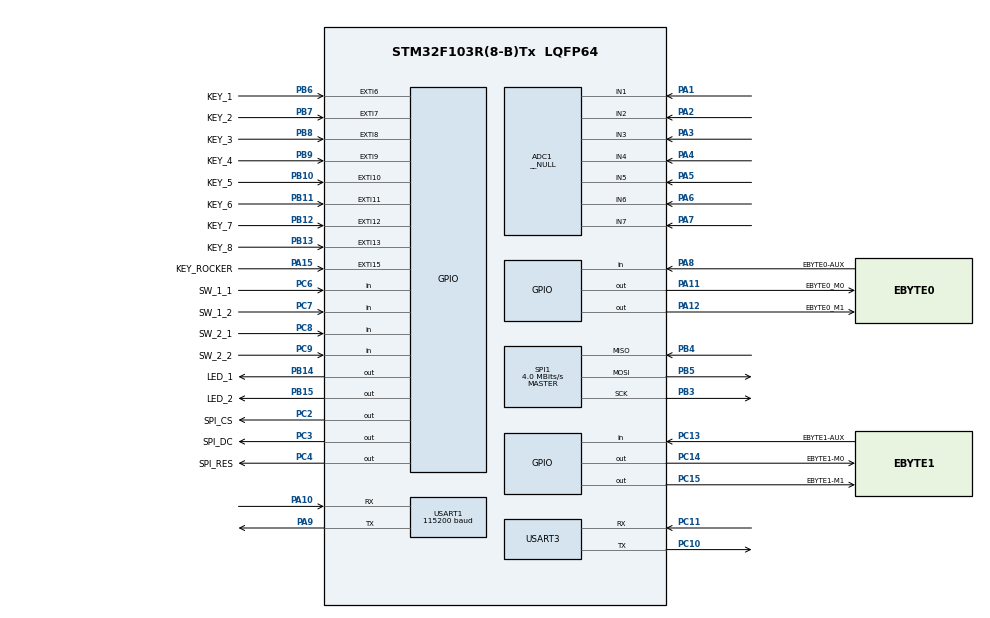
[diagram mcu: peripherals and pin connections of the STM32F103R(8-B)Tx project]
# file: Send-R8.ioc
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ADC1.Channel-0\#ChannelRegularConversion=ADC_CHANNEL_1
ADC1.Channel-1\#ChannelRegularConversion=ADC_CHANNEL_2
ADC1.Channel-2\#ChannelRegularConversion=ADC_CHANNEL_3
ADC1.Channel-3\#ChannelRegularConversion=ADC_CHANNEL_4
ADC1.Channel-4\#ChannelRegularConversion=ADC_CHANNEL_5
ADC1.Channel-5\#ChannelRegularConversion=ADC_CHANNEL_6
ADC1.Channel-6\#ChannelRegularConversion=ADC_CHANNEL_7
ADC1.Channel-IN1=ADC_CHANNEL_1
ADC1.Channel-IN4=ADC_CHANNEL_4
ADC1.Channel-IN5=ADC_CHANNEL_5
ADC1.Channel-IN6=ADC_CHANNEL_6
ADC1.Channel-IN7=ADC_CHANNEL_7
ADC1.ContinuousConvMode=DISABLE
ADC1.DataAlign=ADC_DATAALIGN_RIGHT
ADC1.DiscontinuousConvMode=DISABLE
ADC1.EnableAnalogWatchDog=false
ADC1.EnableInjectedConversion=DISABLE
ADC1.EnableRegularConversion=ENABLE
ADC1.ExternalTrigConv=ADC_EXTERNALTRIGCONV_T3_TRGO
ADC1.Mode=__NULL
ADC1.NbrOfConversion=7
ADC1.Rank-0\#ChannelRegularConversion=1
ADC1.Rank-1\#ChannelRegularConversion=2
ADC1.Rank-2\#ChannelRegularConversion=3
ADC1.Rank-3\#ChannelRegularConversion=4
ADC1.Rank-4\#ChannelRegularConversion=5
ADC1.Rank-5\#ChannelRegularConversion=6
ADC1.Rank-6\#ChannelRegularConversion=7
ADC1.SamplingTime-0\#ChannelRegularConversion=ADC_SAMPLETIME_7CYCLES_5
ADC1.SamplingTime-1\#ChannelRegularConversion=ADC_SAMPLETIME_7CYCLES_5
ADC1.SamplingTime-2\#ChannelRegularConversion=ADC_SAMPLETIME_7CYCLES_5
ADC1.SamplingTime-3\#ChannelRegularConversion=ADC_SAMPLETIME_7CYCLES_5
ADC1.SamplingTime-4\#ChannelRegularConversion=ADC_SAMPLETIME_7CYCLES_5
ADC1.SamplingTime-5\#ChannelRegularConversion=ADC_SAMPLETIME_7CYCLES_5
ADC1.SamplingTime-6\#ChannelRegularConversion=ADC_SAMPLETIME_7CYCLES_5
ADC1.ScanConvMode=ADC_SCAN_ENABLE
ADC1.master=1
Dma.ADC1.1.Direction=DMA_PERIPH_TO_MEMORY
Dma.ADC1.1.Instance=DMA1_Channel1
Dma.ADC1.1.MemDataAlignment=DMA_MDATAALIGN_WORD
Dma.ADC1.1.MemInc=DMA_MINC_ENABLE
Dma.ADC1.1.Mode=DMA_CIRCULAR
Dma.ADC1.1.PeriphDataAlignment=DMA_PDATAALIGN_WORD
Dma.ADC1.1.PeriphInc=DMA_PINC_DISABLE
Dma.ADC1.1.Priority=DMA_PRIORITY_HIGH
Dma.Request0=USART1_TX
Dma.Request1=ADC1
Dma.USART1_TX.0.Direction=DMA_MEMORY_TO_PERIPH
Dma.USART1_TX.0.Instance=DMA1_Channel4
Dma.USART1_TX.0.MemDataAlignment=DMA_MDATAALIGN_BYTE
Dma.USART1_TX.0.MemInc=DMA_MINC_ENABLE
Dma.USART1_TX.0.Mode=DMA_CIRCULAR
Dma.USART1_TX.0.PeriphDataAlignment=DMA_PDATAALIGN_BYTE
Dma.USART1_TX.0.PeriphInc=DMA_PINC_DISABLE
Dma.USART1_TX.0.Priority=DMA_PRIORITY_MEDIUM
Mcu.Family=STM32F1
Mcu.Name=STM32F103R(8-B)Tx
Mcu.Package=LQFP64
NVIC.DMA1_Channel1_IRQn=true\:0\:0\:false\:false\:true\:false\:true\:true
NVIC.DMA1_Channel4_IRQn=true\:0\:0\:false\:false\:true\:false\:true\:true
NVIC.EXTI15_10_IRQn=true\:1\:0\:true\:false\:true\:true\:true\:true
NVIC.EXTI9_5_IRQn=true\:1\:0\:true\:false\:true\:true\:true\:true
NVIC.PriorityGroup=NVIC_PRIORITYGROUP_4
NVIC.TIM2_IRQn=true\:0\:0\:false\:false\:true\:true\:true\:true
NVIC.USART1_IRQn=true\:5\:0\:false\:false\:true\:true\:true\:true
PA1.Signal=ADCx_IN1
PA10.Mode=Asynchronous
PA10.Signal=USART1_RX
PA11.GPIO_Label=EBYTE0_M0
PA11.GPIO_PuPd=GPIO_PULLDOWN
PA11.PinState=GPIO_PIN_RESET
PA11.Signal=GPIO_Output
PA12.GPIO_Label=EBYTE0_M1
PA12.GPIO_PuPd=GPIO_PULLDOWN
PA12.Signal=GPIO_Output
PA13.Mode=Serial_Wire
PA13.Signal=SYS_JTMS-SWDIO
PA14.Mode=Serial_Wire
PA14.Signal=SYS_JTCK-SWCLK
PA15.GPIO_Label=KEY_ROCKER
PA15.GPIO_ModeDefaultEXTI=GPIO_MODE_IT_RISING_FALLING
PA15.GPIO_PuPd=GPIO_PULLUP
PA15.Signal=GPXTI15
PA2.Signal=ADCx_IN2
PA3.Signal=ADCx_IN3
PA4.Signal=ADCx_IN4
PA5.Signal=ADCx_IN5
PA6.Signal=ADCx_IN6
PA7.Signal=ADCx_IN7
PA8.GPIO_Label=EBYTE0-AUX
PA8.Signal=GPIO_Input
PA9.Mode=Asynchronous
PA9.Signal=USART1_TX
PB10.GPIO_Label=KEY_5
PB10.GPIO_ModeDefaultEXTI=GPIO_MODE_IT_RISING_FALLING
PB10.GPIO_PuPd=GPIO_PULLUP
PB10.Signal=GPXTI10
PB11.GPIO_Label=KEY_6
PB11.GPIO_ModeDefaultEXTI=GPIO_MODE_IT_RISING_FALLING
PB11.GPIO_PuPd=GPIO_PULLUP
PB11.Signal=GPXTI11
PB12.GPIO_Label=KEY_7
PB12.GPIO_ModeDefaultEXTI=GPIO_MODE_IT_RISING_FALLING
PB12.GPIO_PuPd=GPIO_PULLUP
PB12.Signal=GPXTI12
PB13.GPIO_Label=KEY_8
PB13.GPIO_ModeDefaultEXTI=GPIO_MODE_IT_RISING_FALLING
PB13.GPIO_PuPd=GPIO_PULLUP
PB13.Signal=GPXTI13
PB14.GPIO_Label=LED_1
PB14.GPIO_PuPd=GPIO_PULLDOWN
PB14.PinState=GPIO_PIN_RESET
PB14.Signal=GPIO_Output
PB15.GPIO_Label=LED_2
PB15.GPIO_PuPd=GPIO_PULLUP
PB15.PinState=GPIO_PIN_SET
PB15.Signal=GPIO_Output
PB3.Mode=Full_Duplex_Master
PB3.Signal=SPI1_SCK
PB4.Mode=Full_Duplex_Master
PB4.Signal=SPI1_MISO
PB5.Mode=Full_Duplex_Master
PB5.Signal=SPI1_MOSI
PB6.GPIO_Label=KEY_1
PB6.GPIO_ModeDefaultEXTI=GPIO_MODE_IT_RISING_FALLING
PB6.GPIO_PuPd=GPIO_PULLUP
PB6.Signal=GPXTI6
PB7.GPIO_Label=KEY_2
PB7.GPIO_ModeDefaultEXTI=GPIO_MODE_IT_RISING_FALLING
PB7.GPIO_PuPd=GPIO_PULLUP
PB7.Signal=GPXTI7
PB8.GPIO_Label=KEY_3
PB8.GPIO_ModeDefaultEXTI=GPIO_MODE_IT_RISING_FALLING
PB8.GPIO_PuPd=GPIO_PULLUP
PB8.Signal=GPXTI8
PB9.GPIO_Label=KEY_4
PB9.GPIO_ModeDefaultEXTI=GPIO_MODE_IT_RISING_FALLING
PB9.GPIO_PuPd=GPIO_PULLUP
PB9.Signal=GPXTI9
PC10.Mode=Asynchronous
PC10.Signal=USART3_TX
PC11.Mode=Asynchronous
PC11.Signal=USART3_RX
PC13-TAMPER-RTC.GPIO_Label=EBYTE1-AUX
PC13-TAMPER-RTC.GPIO_PuPd=GPIO_PULLDOWN
PC13-TAMPER-RTC.Signal=GPIO_Input
PC14-OSC32_IN.GPIO_Label=EBYTE1-M0
PC14-OSC32_IN.GPIO_PuPd=GPIO_PULLDOWN
PC14-OSC32_IN.Signal=GPIO_Output
PC15-OSC32_OUT.GPIO_Label=EBYTE1-M1
PC15-OSC32_OUT.GPIO_PuPd=GPIO_PULLDOWN
PC15-OSC32_OUT.Signal=GPIO_Output
PC2.GPIO_Label=SPI_CS
PC2.Signal=GPIO_Output
PC3.GPIO_Label=SPI_DC
PC3.Signal=GPIO_Output
PC4.GPIO_Label=SPI_RES
PC4.Signal=GPIO_Output
PC6.GPIO_Label=SW_1_1
PC6.GPIO_PuPd=GPIO_PULLUP
PC6.Signal=GPIO_Input
PC7.GPIO_Label=SW_1_2
PC7.GPIO_PuPd=GPIO_PULLUP
PC7.Signal=GPIO_Input
PC8.GPIO_Label=SW_2_1
PC8.GPIO_PuPd=GPIO_PULLUP
PC8.Signal=GPIO_Input
PC9.GPIO_Label=SW_2_2
PC9.GPIO_PuPd=GPIO_PULLUP
PC9.Signal=GPIO_Input
PD0-OSC_IN.Mode=HSE-External-Oscillator
PD0-OSC_IN.Signal=RCC_OSC_IN
PD1-OSC_OUT.Mode=HSE-External-Oscillator
PD1-OSC_OUT.Signal=RCC_OSC_OUT
ProjectManager.HeapSize=0x200
ProjectManager.StackSize=0x400
ProjectManager.TargetToolchain=MDK-ARM V5.27
RCC.APB1Freq_Value=8000000
RCC.APB2Freq_Value=8000000
SH.ADCx_IN1.0=ADC1_IN1,IN1
SH.ADCx_IN2.0=ADC1_IN2,IN2
SH.ADCx_IN3.0=ADC1_IN3,IN3
SH.ADCx_IN4.0=ADC1_IN4,IN4
SH.ADCx_IN5.0=ADC1_IN5,IN5
SH.ADCx_IN6.0=ADC1_IN6,IN6
SH.ADCx_IN7.0=ADC1_IN7,IN7
SPI1.CalculateBaudRate=4.0 MBits/s
SPI1.Direction=SPI_DIRECTION_2LINES
SPI1.Mode=SPI_MODE_MASTER
SPI1.VirtualType=VM_MASTER
TIM2.AutoReloadPreload=TIM_AUTORELOAD_PRELOAD_ENABLE
TIM2.Period=49
TIM2.Prescaler=7999
TIM2.TIM_MasterOutputTrigger=TIM_TRGO_UPDATE
TIM3.AutoReloadPreload=TIM_AUTORELOAD_PRELOAD_ENABLE
TIM3.ClockDivision=TIM_CLOCKDIVISION_DIV1
TIM3.CounterMode=TIM_COUNTERMODE_UP
TIM3.Period=49
TIM3.Prescaler=7999
TIM3.TIM_MasterOutputTrigger=TIM_TRGO_UPDATE
TIM3.TIM_MasterSlaveMode=TIM_MASTERSLAVEMODE_DISABLE
USART1.BaudRate=115200
USART1.Mode=MODE_TX_RX
USART1.Parity=PARITY_NONE
USART1.StopBits=STOPBITS_1
USART1.VirtualMode=VM_ASYNC
USART1.WordLength=WORDLENGTH_8B
USART3.VirtualMode=VM_ASYNC
VP_TIM2_VS_ClockSourceINT.Mode=Internal
VP_TIM3_VS_ClockSourceINT.Mode=Internal
board=custom

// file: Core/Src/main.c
/* USER CODE BEGIN Header */
/**
  ******************************************************************************
  * @file           : main.c
  * @brief          : Main program body
  ******************************************************************************
  * @attention
  *
  * Copyright (c) 2023 STMicroelectronics.
  * All rights reserved.
  *
  * This software is licensed under terms that can be found in the LICENSE file
  * in the root directory of this software component.
  * If no LICENSE file comes with this software, it is provided AS-IS.
  *
  ******************************************************************************
  */
/* USER CODE END Header */
#include "main.h"
#include "adc.h"
#include "dma.h"
#include "spi.h"
#include "tim.h"
#include "usart.h"
#include "gpio.h"

/* USER CODE BEGIN Includes */
#include "remote_control.h"

/* USER CODE END Includes */

/* USER CODE BEGIN PV */
extern rc_info_t rc_info;
/* USER CODE END PV */

void SystemClock_Config(void);

int main(void)
{

  /* MCU Configuration--------------------------------------------------------*/

  /* Reset of all peripherals, Initializes the Flash interface and the Systick. */
  HAL_Init();

  /* Configure the system clock */
  SystemClock_Config();

  /* Initialize all configured peripherals */
  MX_GPIO_Init();
  MX_DMA_Init();
  MX_USART1_UART_Init();
  MX_ADC1_Init();
  MX_TIM3_Init();
  MX_SPI1_Init();
  MX_USART3_UART_Init();
  MX_TIM2_Init();
  /* USER CODE BEGIN 2 */
  remote_control_init(&rc_info);
  rc_info.key[0] = !HAL_GPIO_ReadPin(KEY_1_GPIO_Port, KEY_1_Pin);
  rc_info.key[1] = !HAL_GPIO_ReadPin(KEY_2_GPIO_Port, KEY_2_Pin);
  rc_info.key[2] = !HAL_GPIO_ReadPin(KEY_3_GPIO_Port, KEY_3_Pin);
  rc_info.key[3] = !HAL_GPIO_ReadPin(KEY_4_GPIO_Port, KEY_4_Pin);
  rc_info.key[4] = !HAL_GPIO_ReadPin(KEY_5_GPIO_Port, KEY_5_Pin);
  rc_info.key[5] = !HAL_GPIO_ReadPin(KEY_6_GPIO_Port, KEY_6_Pin);
  rc_info.key[6] = !HAL_GPIO_ReadPin(KEY_7_GPIO_Port, KEY_7_Pin);
  rc_info.key[7] = !HAL_GPIO_ReadPin(KEY_8_GPIO_Port, KEY_8_Pin);
  rc_info.key[8] = !HAL_GPIO_ReadPin(KEY_ROCKER_GPIO_Port, KEY_ROCKER_Pin);
  /* USER CODE END 2 */

  /* Infinite loop */
  /* USER CODE BEGIN WHILE */
  while (1)
  {
    remote_control_transmit(&rc_info);

    HAL_Delay(40);
    /* USER CODE END WHILE */

  }
}

void SystemClock_Config(void)
{
  RCC_OscInitTypeDef RCC_OscInitStruct = {0};
  RCC_ClkInitTypeDef RCC_ClkInitStruct = {0};
  RCC_PeriphCLKInitTypeDef PeriphClkInit = {0};

  /** Initializes the RCC Oscillators according to the specified parameters
  * in the RCC_OscInitTypeDef structure.
  */
  RCC_OscInitStruct.OscillatorType = RCC_OSCILLATORTYPE_HSI;
  RCC_OscInitStruct.HSIState = RCC_HSI_ON;
  RCC_OscInitStruct.HSICalibrationValue = RCC_HSICALIBRATION_DEFAULT;
  RCC_OscInitStruct.PLL.PLLState = RCC_PLL_NONE;
  if (HAL_RCC_OscConfig(&RCC_OscInitStruct) != HAL_OK)
  {
    Error_Handler();
  }

  /** Initializes the CPU, AHB and APB buses clocks
  */
  RCC_ClkInitStruct.ClockType = RCC_CLOCKTYPE_HCLK|RCC_CLOCKTYPE_SYSCLK
                              |RCC_CLOCKTYPE_PCLK1|RCC_CLOCKTYPE_PCLK2;
  RCC_ClkInitStruct.SYSCLKSource = RCC_SYSCLKSOURCE_HSI;
  RCC_ClkInitStruct.AHBCLKDivider = RCC_SYSCLK_DIV1;
  RCC_ClkInitStruct.APB1CLKDivider = RCC_HCLK_DIV1;
  RCC_ClkInitStruct.APB2CLKDivider = RCC_HCLK_DIV1;

  if (HAL_RCC_ClockConfig(&RCC_ClkInitStruct, FLASH_LATENCY_0) != HAL_OK)
  {
    Error_Handler();
  }
  PeriphClkInit.PeriphClockSelection = RCC_PERIPHCLK_ADC;
  PeriphClkInit.AdcClockSelection = RCC_ADCPCLK2_DIV2;
  if (HAL_RCCEx_PeriphCLKConfig(&PeriphClkInit) != HAL_OK)
  {
    Error_Handler();
  }
}

void Error_Handler(void)
{
  __disable_irq();
  while (1)
  {
  }
}
